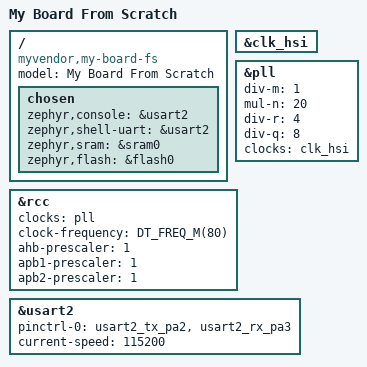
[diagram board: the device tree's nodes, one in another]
/dts-v1/;
#include <st/l4/stm32l476Xg.dtsi>
#include <st/l4/stm32l476r(c-e-g)tx-pinctrl.dtsi>

/ {
	model = "My Board From Scratch";
	compatible = "myvendor,my-board-fs";

	chosen {
		zephyr,console = &usart2;
		zephyr,shell-uart = &usart2;
		zephyr,sram = &sram0;
		zephyr,flash = &flash0;
	};
};

&clk_hsi {
	status = "okay";
};

&pll {
	div-m = <1>;
	mul-n = <20>;
	div-r = <4>;
	div-q = <8>;
	clocks = <&clk_hsi>;
	status = "okay";
};

&rcc {
	clocks = <&pll>;
	clock-frequency = <DT_FREQ_M(80)>;
	ahb-prescaler = <1>;
	apb1-prescaler = <1>;
	apb2-prescaler = <1>;
};

&usart2 {
	pinctrl-0 = <&usart2_tx_pa2 &usart2_rx_pa3>;
	pinctrl-names = "default";
	current-speed = <115200>;
	status = "okay";
};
